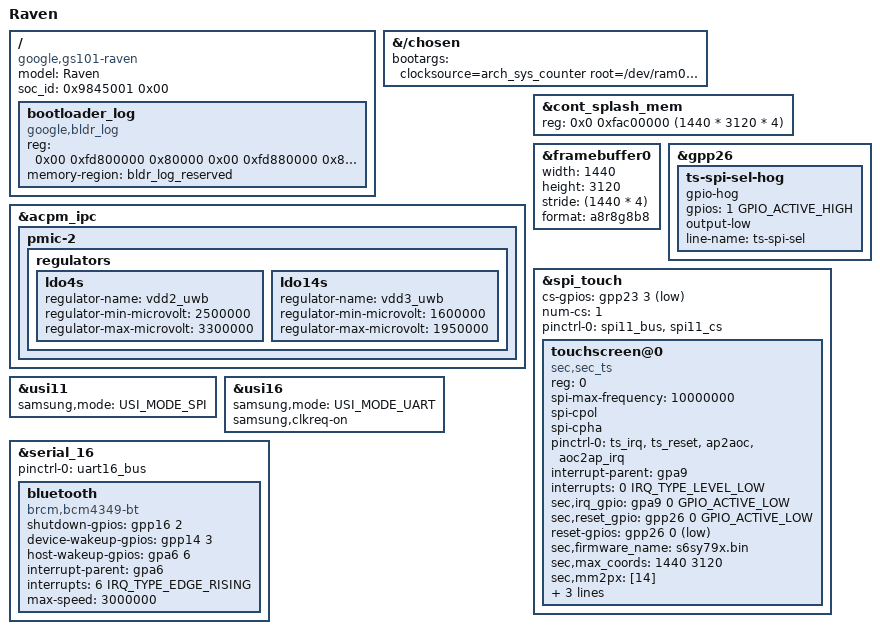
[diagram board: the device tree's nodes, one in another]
// SPDX-License-Identifier: GPL-2.0-only
/*
 * Raven Device Tree
 *
 * Copyright 2021-2023 Google LLC
 * Copyright 2023-2025 Linaro Ltd
 */

/dts-v1/;

#include "gs101-pixel-common.dtsi"
#include "gs101-overlay-anchors.dtsi"

/ {
	model = "Raven";
	compatible = "google,gs101-raven", "google,gs101";
	/*
	 * The bootloader picks the base FDT out of the vendor_boot dtb
	 * region by comparing this root property against the SoC revision
	 * that is fitted.  The stock vendor_boot carries two concatenated
	 * FDTs, soc_id <0x9845000 0x00> and <0x9845001 0x00>, and on this
	 * unit the live /proc/device-tree is the second one (cal_if has
	 * minmax_idx, exynos-acme/domain@0 has no max-volt, ip_ver is
	 * 0x14020100, evt-ver is [01]).  Without the property the
	 * bootloader has no selection key and reports
	 * "Enter reason: boot failure".
	 */
	soc_id = <0x9845001 0x00>;

	bootloader_log {
		compatible = "google,bldr_log";
		reg = <0x00 0xfd800000 0x80000 0x00 0xfd880000 0x80000>;
		reg-names = "bl_log", "bl_old_log";
		memory-region = <&bldr_log_reserved>;
	};
};

&{/chosen} {
	/*
	 * The bootloader parses and rewrites this property: it strips
	 * earlycon=, console= and androidboot.* tokens, keeps the rest and
	 * appends its own vendor_cmdline and board suffix.  No serial
	 * console token is used here (the UART is not broken out, and the
	 * samsung early busyuart would spin unbounded if the UART clock is
	 * off); early kernel log evidence comes from ramoops/pstore instead.
	 * The pmOS initramfs keys are repeated in the vendor_boot
	 * vendor_cmdline so they survive whichever channel is honoured.
	 *
	 * stdout-path is deleted: neither stock FDT in the vendor_boot
	 * dtb region carries it, and console= on the command line sets
	 * console_set_on_cmdline, which makes of_console_check() refuse
	 * to turn the property into a preferred console.  It can select
	 * nothing here either, so pstore/ramoops stays the only sink.
	 *
	 * console=tty0 selects the VT console so that printk() output
	 * reaches the framebuffer console (VT -> fbcon -> /dev/fb0 ->
	 * panel).  It has to come before the bootloader's own suffix,
	 * because the bootloader appends console=null last and that token
	 * would otherwise become the preferred console.  console_setup()
	 * decodes "tty0" to the name "tty" with index 0, which is what
	 * try_enable_preferred_console() matches against the VT console
	 * driver (name "tty", index -1).  consoleblank=0 keeps the
	 * framebuffer console from being blanked out, and
	 * fbcon=font:TER16x32 selects a font that is legible on the
	 * 1440x3120 panel.
	 */
	/delete-property/ stdout-path;
	bootargs = "clocksource=arch_sys_counter root=/dev/ram0 firmware_class.path=/vendor/firmware reserve-fimc=0xffffff90f9fe0000 clk_ignore_unused loop.max_part=7 coherent_pool=4M no_console_suspend softlockup_panic=1 loglevel=8 regulator_ignore_unused console=tty0 fbcon=font:TER16x32 consoleblank=0 pmos_boot_uuid=dcca49fa-fc71-498e-9f4f-09f2b80edaf1 pmos_root_uuid=0bcaadf4-9a11-4422-9a03-e297f1e97aaf pmos_rootfsopts=defaults";
};

&acpm_ipc {
	pmic-2 {
		regulators {
			ldo4s {
				regulator-name = "vdd2_uwb";
				regulator-min-microvolt = <2500000>;
				regulator-max-microvolt = <3300000>;
			};

			ldo14s {
				regulator-name = "vdd3_uwb";
				regulator-min-microvolt = <1600000>;
				regulator-max-microvolt = <1950000>;
			};
		};
	};
};

&cont_splash_mem {
	reg = <0x0 0xfac00000 (1440 * 3120 * 4)>;

	status = "okay";
};

&framebuffer0 {
	width = <1440>;
	height = <3120>;
	stride = <(1440 * 4)>;
	format = "a8r8g8b8";

	status = "okay";
};

&gpp26 {
	/* TS_SPI_SEL: low = AP owns the touch SPI bus, high = AOC */
	ts-spi-sel-hog {
		gpio-hog;
		gpios = <1 GPIO_ACTIVE_HIGH>;
		output-low;
		line-name = "ts-spi-sel";
	};
};

&spi_touch {
	cs-gpios = <&gpp23 3 GPIO_ACTIVE_LOW>;
	num-cs = <1>;
	pinctrl-0 = <&spi11_bus &spi11_cs>;
	pinctrl-names = "default";
	status = "okay";

	/delete-node/ touchscreen@0;

	touchscreen@0 {
		compatible = "sec,sec_ts";
		reg = <0>;
		spi-max-frequency = <10000000>;
		spi-cpol;
		spi-cpha;

		pinctrl-0 = <&ts_irq &ts_reset &ap2aoc &aoc2ap_irq>;
		pinctrl-names = "default";

		interrupt-parent = <&gpa9>;
		interrupts = <0 IRQ_TYPE_LEVEL_LOW>;

		sec,irq_gpio = <&gpa9 0 GPIO_ACTIVE_LOW>;
		sec,reset_gpio = <&gpp26 0 GPIO_ACTIVE_LOW>;
		reset-gpios = <&gpp26 0 GPIO_ACTIVE_LOW>;

		sec,firmware_name = "s6sy79x.bin";
		sec,max_coords = <1440 3120>;
		sec,mm2px = [14];
		sec,mis_cal_check = <1>;

		vdd-supply = <&s2mpg10_ldo25m>;
		avdd-supply = <&s2mpg10_ldo26m>;
	};
};

&usi11 {
	samsung,mode = <USI_MODE_SPI>;
	status = "okay";
};

&usi16 {
	samsung,mode = <USI_MODE_UART>;
	samsung,clkreq-on;
	status = "okay";
};

&serial_16 {
	status = "okay";
	pinctrl-0 = <&uart16_bus>;
	pinctrl-names = "default";

	bluetooth {
		compatible = "brcm,bcm4349-bt", "brcm,bcm43438-bt";
		shutdown-gpios = <&gpp16 2 GPIO_ACTIVE_HIGH>;
		device-wakeup-gpios = <&gpp14 3 GPIO_ACTIVE_HIGH>;
		host-wakeup-gpios = <&gpa6 6 GPIO_ACTIVE_HIGH>;
		interrupt-parent = <&gpa6>;
		interrupts = <6 IRQ_TYPE_EDGE_RISING>;
		interrupt-names = "host-wakeup";
		max-speed = <3000000>;
	};
};
